VERSION ""

NS_ :

BS_:

BU_:

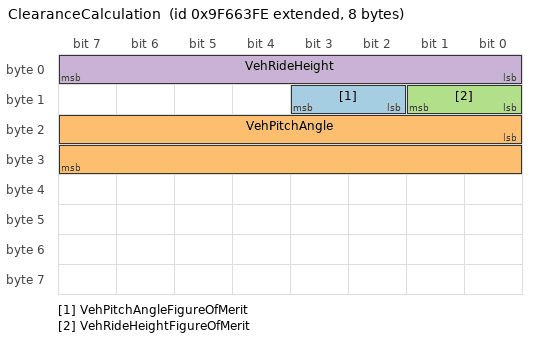
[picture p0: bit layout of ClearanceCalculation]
BO_ 2314626046 ClearanceCalculation: 8 Vector__XXX
 SG_ VehPitchAngleFigureOfMerit : 10|2@1+ (1,0) [0|3] "" Vector__XXX
 SG_ VehPitchAngle : 16|16@1+ (0.002,-64) [-64|64.51] "deg" Vector__XXX
 SG_ VehRideHeightFigureOfMerit : 8|2@1+ (1,0) [0|3] "" Vector__XXX
 SG_ VehRideHeight : 0|8@1+ (2,0) [0|510] "" Vector__XXX

CM_ BO_ 2314626046 "Clearance Calculation Information
The Clearance Calculation Information message shall provide a calculation value of vehicle ride height, pitch angle and status of these signals";
CM_ SG_ 2314626046 VehPitchAngleFigureOfMerit "Figure of merit for vehicle pitch angle measurement.

00 - Vehicle pitch angle fully functional.  Data is within sensor specification. 
01 - Vehicle pitch angle degraded.  Data is suspect due to environmental conditions.
10 - Error
11 - Not available";
CM_ SG_ 2314626046 VehPitchAngle "Vehicle Pitch Angle";
CM_ SG_ 2314626046 VehRideHeightFigureOfMerit "Figure of merit for vehicle ride height measurement.

00 - Vehicle ride height fully functional.  Data is within sensor specification. 
01 - Vehicle ride height degraded.  Data is suspect due to environmental conditions.
10 - Error
11 - Not available";
CM_ SG_ 2314626046 VehRideHeight "Minimum value from ride height sensors measured on axles including distance unsprung mass";
BA_DEF_ SG_  "SigType" ENUM  "Default","Range","RangeSigned","ASCII","Discrete","Control","ReferencePGN","DTC","StringDelimiter","StringLength","StringLengthControl","MessageCounter","MessageChecksum";
BA_DEF_ SG_  "GenSigEVName" STRING ;
BA_DEF_ SG_  "GenSigILSupport" ENUM  "No","Yes";
BA_DEF_ SG_  "GenSigSendType" ENUM  "Cyclic","OnWrite","OnWriteWithRepetition","OnChange","OnChangeWithRepetition","IfActive","IfActiveWithRepetition","NoSigSendType";
BA_DEF_ SG_  "GenSigStartValue" INT 0 2147483647;
BA_DEF_ BO_  "GenMsgILSupport" ENUM  "No","Yes";
BA_DEF_ BU_  "NmStationAddress" INT 0 255;
BA_DEF_ BO_  "GenMsgSendType" ENUM  "cyclic","NotUsed","IfActive","NotUsed","NotUsed","NotUsed","NotUsed","NotUsed","noMsgSendType";
BA_DEF_ BO_  "GenMsgRequestable" INT 0 1;
BA_DEF_ BO_  "GenMsgCycleTime" INT 0 3600000;
BA_DEF_  "DBName" STRING ;
BA_DEF_  "BusType" STRING ;
BA_DEF_  "ProtocolType" STRING ;
BA_DEF_ BO_  "VFrameFormat" ENUM  "StandardCAN","ExtendedCAN","reserved","J1939PG";
BA_DEF_ BO_  "Producer" STRING ;
BA_DEF_DEF_  "SigType" "Default";
BA_DEF_DEF_  "GenSigEVName" "Env@Nodename_@Signame";
BA_DEF_DEF_  "GenSigILSupport" "Yes";
BA_DEF_DEF_  "GenSigSendType" "NoSigSendType";
BA_DEF_DEF_  "GenSigStartValue" 0;
BA_DEF_DEF_  "GenMsgILSupport" "Yes";
BA_DEF_DEF_  "NmStationAddress" 254;
BA_DEF_DEF_  "GenMsgSendType" "noMsgSendType";
BA_DEF_DEF_  "GenMsgRequestable" 1;
BA_DEF_DEF_  "GenMsgCycleTime" 0;
BA_DEF_DEF_  "DBName" "";
BA_DEF_DEF_  "BusType" "CAN";
BA_DEF_DEF_  "ProtocolType" "J1939";
BA_DEF_DEF_  "VFrameFormat" "J1939PG";
BA_DEF_DEF_  "Producer" "DTS";
BA_ "DBName" "Clearance";
BA_ "Producer" BO_ 2314626046 "SCS";
BA_ "GenMsgCycleTime" BO_ 2314626046 100;
BA_ "GenMsgSendType" BO_ 2314626046 0;
BA_ "GenSigStartValue" SG_ 2314626046 VehPitchAngle 32000;
VAL_ 2314626046 VehPitchAngleFigureOfMerit 3 "Vehicle Pitch Angle Not Available" 2 "Vehicle Pitch Angle Error" 1 "Vehicle Pitch Angle degraded" 0 "Vehicle Pitch Angle fully functional" ;
VAL_ 2314626046 VehRideHeightFigureOfMerit 3 "Vehicle Ride Height Not Available" 2 "Vehicle Ride Height Error" 1 "Vehicle Ride Height degraded" 0 "Vehicle Ride Height fully functional" ;
